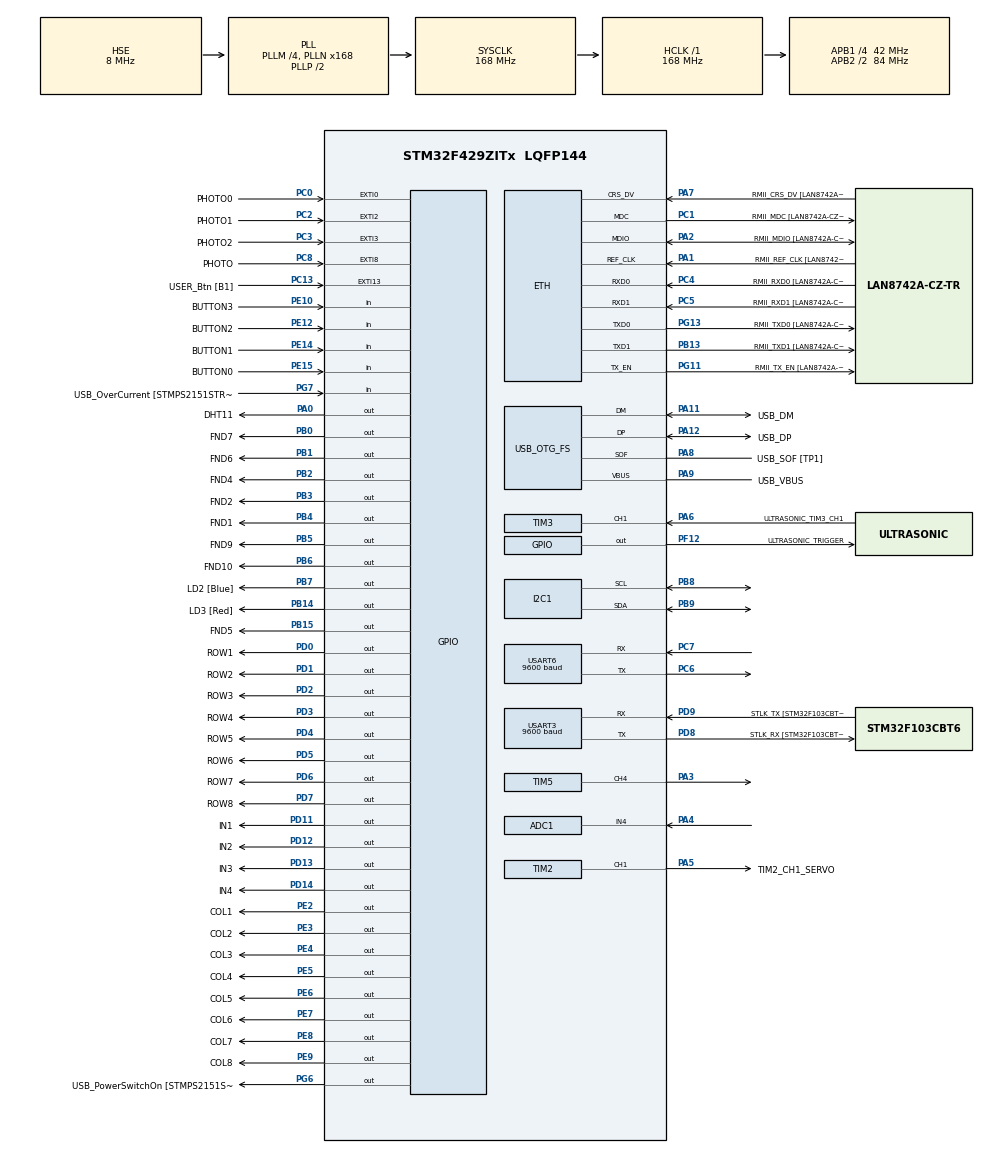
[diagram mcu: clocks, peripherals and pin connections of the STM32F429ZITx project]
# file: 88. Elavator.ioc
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ADC1.Channel-1\#ChannelRegularConversion=ADC_CHANNEL_4
ADC1.ContinuousConvMode=ENABLE
ADC1.NbrOfConversionFlag=1
ADC1.Rank-1\#ChannelRegularConversion=1
ADC1.SamplingTime-1\#ChannelRegularConversion=ADC_SAMPLETIME_480CYCLES
ADC1.master=1
ETH.MediaInterface=HAL_ETH_RMII_MODE
FREERTOS.Mutexes01=myMutex01,Dynamic,NULL
FREERTOS.Tasks01=defaultTask,24,128,StartDefaultTask,Default,NULL,Dynamic,NULL,NULL;Task1,8,128,Task1_func,Default,NULL,Dynamic,NULL,NULL;Task2,8,128,Task2_func,Default,NULL,Dynamic,NULL,NULL;Task3,8,128,Task3_func,Default,NULL,Dynamic,NULL,NULL
FREERTOS.configUSE_NEWLIB_REENTRANT=1
Mcu.Family=STM32F4
Mcu.Name=STM32F429ZITx
Mcu.Package=LQFP144
NVIC.ADC_IRQn=true\:5\:0\:false\:false\:true\:true\:true\:true\:true
NVIC.EXTI0_IRQn=true\:5\:0\:false\:false\:true\:true\:true\:true\:true
NVIC.EXTI2_IRQn=true\:5\:0\:false\:false\:true\:true\:true\:true\:true
NVIC.EXTI3_IRQn=true\:5\:0\:false\:false\:true\:true\:true\:true\:true
NVIC.EXTI9_5_IRQn=true\:5\:0\:false\:false\:true\:true\:true\:true\:true
NVIC.PriorityGroup=NVIC_PRIORITYGROUP_4
NVIC.TIM1_TRG_COM_TIM11_IRQn=true\:5\:0\:false\:false\:true\:true\:true\:true\:true
NVIC.TIM1_UP_TIM10_IRQn=true\:5\:0\:false\:false\:true\:true\:true\:true\:true
NVIC.TIM2_IRQn=true\:5\:0\:false\:false\:true\:true\:true\:true\:true
NVIC.TIM3_IRQn=true\:5\:0\:false\:false\:true\:true\:true\:true\:true
NVIC.TIM4_IRQn=true\:5\:0\:false\:false\:true\:true\:true\:true\:true
NVIC.TIM5_IRQn=true\:5\:0\:false\:false\:true\:true\:true\:true\:true
NVIC.TIM6_DAC_IRQn=true\:15\:0\:false\:false\:true\:false\:false\:true\:true
NVIC.TimeBase=TIM6_DAC_IRQn
NVIC.TimeBaseIP=TIM6
NVIC.USART3_IRQn=true\:5\:0\:false\:false\:true\:true\:true\:true\:true
NVIC.USART6_IRQn=true\:5\:0\:false\:false\:true\:true\:true\:true\:true
PA0/WKUP.GPIO_Label=DHT11
PA0/WKUP.Signal=GPIO_Output
PA1.GPIO_Label=RMII_REF_CLK [LAN8742A-CZ-TR_REFCLK0]
PA1.Mode=RMII
PA1.Signal=ETH_REF_CLK
PA10.GPIO_Label=USB_ID
PA10.Signal=USB_OTG_FS_ID
PA11.GPIO_Label=USB_DM
PA11.Mode=Device_Only
PA11.Signal=USB_OTG_FS_DM
PA12.GPIO_Label=USB_DP
PA12.Mode=Device_Only
PA12.Signal=USB_OTG_FS_DP
PA13.GPIO_Label=TMS
PA13.Mode=Serial_Wire
PA13.Signal=SYS_JTMS-SWDIO
PA14.GPIO_Label=TCK
PA14.Mode=Serial_Wire
PA14.Signal=SYS_JTCK-SWCLK
PA2.GPIO_Label=RMII_MDIO [LAN8742A-CZ-TR_MDIO]
PA2.Mode=RMII
PA2.Signal=ETH_MDIO
PA3.Signal=S_TIM5_CH4
PA4.Signal=ADCx_IN4
PA5.GPIO_Label=TIM2_CH1_SERVO
PA5.Signal=S_TIM2_CH1_ETR
PA6.GPIO_Label=ULTRASONIC_TIM3_CH1
PA6.Signal=S_TIM3_CH1
PA7.GPIO_Label=RMII_CRS_DV [LAN8742A-CZ-TR_CRS_DV]
PA7.Mode=RMII
PA7.Signal=ETH_CRS_DV
PA8.GPIO_Label=USB_SOF [TP1]
PA8.Mode=Activate_SOF_FS
PA8.Signal=USB_OTG_FS_SOF
PA9.GPIO_Label=USB_VBUS
PA9.Mode=Activate_VBUS
PA9.Signal=USB_OTG_FS_VBUS
PB0.GPIO_Label=FND7
PB0.Signal=GPIO_Output
PB1.GPIO_Label=FND6
PB1.Signal=GPIO_Output
PB13.GPIO_Label=RMII_TXD1 [LAN8742A-CZ-TR_TXD1]
PB13.Mode=RMII
PB13.Signal=ETH_TXD1
PB14.GPIO_Label=LD3 [Red]
PB14.Signal=GPIO_Output
PB15.GPIO_Label=FND5
PB15.Signal=GPIO_Output
PB2/BOOT1.GPIO_Label=FND4
PB2/BOOT1.Signal=GPIO_Output
PB3.GPIO_Label=FND2
PB3.Signal=GPIO_Output
PB4.GPIO_Label=FND1
PB4.Signal=GPIO_Output
PB5.GPIO_Label=FND9
PB5.Signal=GPIO_Output
PB6.GPIO_Label=FND10
PB6.Signal=GPIO_Output
PB7.GPIO_Label=LD2 [Blue]
PB7.Signal=GPIO_Output
PB8.Mode=I2C
PB8.Signal=I2C1_SCL
PB9.Mode=I2C
PB9.Signal=I2C1_SDA
PC0.GPIO_Label=PHOTO0
PC0.Signal=GPXTI0
PC1.GPIO_Label=RMII_MDC [LAN8742A-CZ-TR_MDC]
PC1.Mode=RMII
PC1.Signal=ETH_MDC
PC13.GPIO_Label=USER_Btn [B1]
PC13.Signal=GPXTI13
PC14/OSC32_IN.Mode=LSE-External-Oscillator
PC14/OSC32_IN.Signal=RCC_OSC32_IN
PC15/OSC32_OUT.Mode=LSE-External-Oscillator
PC15/OSC32_OUT.Signal=RCC_OSC32_OUT
PC2.GPIO_Label=PHOTO1
PC2.Signal=GPXTI2
PC3.GPIO_Label=PHOTO2
PC3.Signal=GPXTI3
PC4.GPIO_Label=RMII_RXD0 [LAN8742A-CZ-TR_RXD0]
PC4.Mode=RMII
PC4.Signal=ETH_RXD0
PC5.GPIO_Label=RMII_RXD1 [LAN8742A-CZ-TR_RXD1]
PC5.Mode=RMII
PC5.Signal=ETH_RXD1
PC6.Mode=Asynchronous
PC6.Signal=USART6_TX
PC7.Mode=Asynchronous
PC7.Signal=USART6_RX
PC8.GPIO_Label=PHOTO
PC8.Signal=GPXTI8
PD0.GPIO_Label=ROW1
PD0.Signal=GPIO_Output
PD1.GPIO_Label=ROW2
PD1.Signal=GPIO_Output
PD11.GPIO_Label=IN1
PD11.Signal=GPIO_Output
PD12.GPIO_Label=IN2
PD12.Signal=GPIO_Output
PD13.GPIO_Label=IN3
PD13.Signal=GPIO_Output
PD14.GPIO_Label=IN4
PD14.Signal=GPIO_Output
PD2.GPIO_Label=ROW3
PD2.Signal=GPIO_Output
PD3.GPIO_Label=ROW4
PD3.Signal=GPIO_Output
PD4.GPIO_Label=ROW5
PD4.Signal=GPIO_Output
PD5.GPIO_Label=ROW6
PD5.Signal=GPIO_Output
PD6.GPIO_Label=ROW7
PD6.Signal=GPIO_Output
PD7.GPIO_Label=ROW8
PD7.Signal=GPIO_Output
PD8.GPIO_Label=STLK_RX [STM32F103CBT6_PA3]
PD8.Mode=Asynchronous
PD8.Signal=USART3_TX
PD9.GPIO_Label=STLK_TX [STM32F103CBT6_PA2]
PD9.Mode=Asynchronous
PD9.Signal=USART3_RX
PE10.GPIO_Label=BUTTON3
PE10.Signal=GPIO_Input
PE12.GPIO_Label=BUTTON2
PE12.Signal=GPIO_Input
PE14.GPIO_Label=BUTTON1
PE14.Signal=GPIO_Input
PE15.GPIO_Label=BUTTON0
PE15.Signal=GPIO_Input
PE2.GPIO_Label=COL1
PE2.Signal=GPIO_Output
PE3.GPIO_Label=COL2
PE3.Signal=GPIO_Output
PE4.GPIO_Label=COL3
PE4.Signal=GPIO_Output
PE5.GPIO_Label=COL4
PE5.Signal=GPIO_Output
PE6.GPIO_Label=COL5
PE6.Signal=GPIO_Output
PE7.GPIO_Label=COL6
PE7.Signal=GPIO_Output
PE8.GPIO_Label=COL7
PE8.Signal=GPIO_Output
PE9.GPIO_Label=COL8
PE9.Signal=GPIO_Output
PF12.GPIO_Label=ULTRASONIC_TRIGGER
PF12.Signal=GPIO_Output
PG11.GPIO_Label=RMII_TX_EN [LAN8742A-CZ-TR_TXEN]
PG11.Mode=RMII
PG11.Signal=ETH_TX_EN
PG13.GPIO_Label=RMII_TXD0 [LAN8742A-CZ-TR_TXD0]
PG13.Mode=RMII
PG13.Signal=ETH_TXD0
PG6.GPIO_Label=USB_PowerSwitchOn [STMPS2151STR_EN]
PG6.Signal=GPIO_Output
PG7.GPIO_Label=USB_OverCurrent [STMPS2151STR_FAULT]
PG7.Signal=GPIO_Input
PH0/OSC_IN.GPIO_Label=MCO [STM32F103CBT6_PA8]
PH0/OSC_IN.Mode=HSE-External-Clock-Source
PH0/OSC_IN.Signal=RCC_OSC_IN
PH1/OSC_OUT.Mode=HSE-External-Clock-Source
PH1/OSC_OUT.Signal=RCC_OSC_OUT
ProjectManager.HeapSize=0x200
ProjectManager.StackSize=0x400
ProjectManager.TargetToolchain=STM32CubeIDE
RCC.48MHZClocksFreq_Value=48000000
RCC.AHBFreq_Value=168000000
RCC.APB1CLKDivider=RCC_HCLK_DIV4
RCC.APB1Freq_Value=42000000
RCC.APB1TimFreq_Value=84000000
RCC.APB2CLKDivider=RCC_HCLK_DIV2
RCC.APB2Freq_Value=84000000
RCC.APB2TimCLKDivider=2
RCC.APB2TimFreq_Value=168000000
RCC.CortexFreq_Value=168000000
RCC.HCLKFreq_Value=168000000
RCC.HSE_VALUE=8000000
RCC.HSI_VALUE=16000000
RCC.PLLM=4
RCC.PLLMUL=RCC_PLL_MUL9
RCC.PLLN=168
RCC.PLLQ=7
RCC.PRESCALERUSB=RCC_USBCLKSOURCE_PLL_DIV1_5
RCC.SYSCLKFreq_VALUE=168000000
RCC.SYSCLKSource=RCC_SYSCLKSOURCE_PLLCLK
RCC.SYSCLKSourceVirtual=RCC_SYSCLKSOURCE_PLLCLK
RCC.USBFreq_Value=48000000
RCC.VCOOutputFreq_Value=336000000
RTC.Date=16
RTC.Hours=9
RTC.Minutes=38
RTC.Month=RTC_MONTH_OCTOBER
RTC.Year=23
SH.ADCx_IN4.0=ADC1_IN4,IN4
SH.S_TIM2_CH1_ETR.0=TIM2_CH1,PWM Generation1 CH1
SH.S_TIM3_CH1.0=TIM3_CH1,Input_Capture1_from_TI1
SH.S_TIM5_CH4.0=TIM5_CH4,PWM Generation4 CH4
TIM10.Period=10000-1
TIM10.Prescaler=168-1
TIM11.Prescaler=168-1
TIM2.Channel-PWM\ Generation1\ CH1=TIM_CHANNEL_1
TIM2.Period=1000-1
TIM2.Prescaler=1680-1
TIM2.Pulse-PWM\ Generation1\ CH1=500-1
TIM3.Channel-Input_Capture1_from_TI1=TIM_CHANNEL_1
TIM3.ICPolarity_CH1=TIM_INPUTCHANNELPOLARITY_BOTHEDGE
TIM3.Prescaler=84-1
TIM4.Period=100-1
TIM4.Prescaler=840-1
TIM5.Channel-PWM\ Generation4\ CH4=TIM_CHANNEL_4
TIM5.Period=400-1
TIM5.Prescaler=52.5-1
TIM5.Pulse-PWM\ Generation4\ CH4=200-1
USART3.BaudRate=9600
USART3.VirtualMode=VM_ASYNC
USART6.BaudRate=9600
USART6.VirtualMode=VM_ASYNC
USB_OTG_FS.VirtualMode=Device_Only
VP_FREERTOS_VS_CMSIS_V2.Mode=CMSIS_V2
VP_RTC_VS_RTC_Activate.Mode=RTC_Enabled
VP_RTC_VS_RTC_Calendar.Mode=RTC_Calendar
VP_SYS_VS_tim6.Mode=TIM6
VP_TIM10_VS_ClockSourceINT.Mode=Enable_Timer
VP_TIM11_VS_ClockSourceINT.Mode=Enable_Timer
VP_TIM4_VS_ClockSourceINT.Mode=Internal
VP_TIM5_VS_ClockSourceINT.Mode=Internal
board=NUCLEO-F429ZI

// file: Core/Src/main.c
/* USER CODE BEGIN Header */
/**
  ******************************************************************************
  * @file           : main.c
  * @brief          : Main program body
  ******************************************************************************
  * @attention
  *
  * Copyright (c) 2023 STMicroelectronics.
  * All rights reserved.
  *
  * This software is licensed under terms that can be found in the LICENSE file
  * in the root directory of this software component.
  * If no LICENSE file comes with this software, it is provided AS-IS.
  *
  ******************************************************************************
  */
/* USER CODE END Header */
#include "main.h"
#include "string.h"
#include "cmsis_os.h"

ETH_TxPacketConfig TxConfig;
ETH_DMADescTypeDef  DMARxDscrTab[ETH_RX_DESC_CNT]; /* Ethernet Rx DMA Descriptors */
ETH_DMADescTypeDef  DMATxDscrTab[ETH_TX_DESC_CNT]; /* Ethernet Tx DMA Descriptors */

ADC_HandleTypeDef hadc1;

ETH_HandleTypeDef heth;

I2C_HandleTypeDef hi2c1;

RTC_HandleTypeDef hrtc;

TIM_HandleTypeDef htim2;
TIM_HandleTypeDef htim3;
TIM_HandleTypeDef htim4;
TIM_HandleTypeDef htim5;
TIM_HandleTypeDef htim10;
TIM_HandleTypeDef htim11;

UART_HandleTypeDef huart3;
UART_HandleTypeDef huart6;

PCD_HandleTypeDef hpcd_USB_OTG_FS;

/* Definitions for defaultTask */
osThreadId_t defaultTaskHandle;
const osThreadAttr_t defaultTask_attributes = {
  .name = "defaultTask",
  .stack_size = 128 * 4,
  .priority = (osPriority_t) osPriorityNormal,
};
/* Definitions for Task1 */
osThreadId_t Task1Handle;
const osThreadAttr_t Task1_attributes = {
  .name = "Task1",
  .stack_size = 128 * 4,
  .priority = (osPriority_t) osPriorityLow,
};
/* Definitions for Task2 */
osThreadId_t Task2Handle;
const osThreadAttr_t Task2_attributes = {
  .name = "Task2",
  .stack_size = 128 * 4,
  .priority = (osPriority_t) osPriorityLow,
};
/* Definitions for Task3 */
osThreadId_t Task3Handle;
const osThreadAttr_t Task3_attributes = {
  .name = "Task3",
  .stack_size = 128 * 4,
  .priority = (osPriority_t) osPriorityLow,
};
/* Definitions for myMutex01 */
osMutexId_t myMutex01Handle;
const osMutexAttr_t myMutex01_attributes = {
  .name = "myMutex01"
};
/* USER CODE BEGIN PV */
uint8_t rx_data;   // uart3 rx data
uint8_t bt_rx_data;   // uart6 bt rx data
volatile int TIM10_10ms_counter=0;
volatile int TIM10_10ms_ultrasonic=0;
/* USER CODE END PV */

void SystemClock_Config(void);
static void MX_GPIO_Init(void);
static void MX_USART3_UART_Init(void);
static void MX_USB_OTG_FS_PCD_Init(void);
static void MX_USART6_UART_Init(void);
static void MX_TIM10_Init(void);
static void MX_TIM11_Init(void);
static void MX_TIM3_Init(void);
static void MX_TIM4_Init(void);
static void MX_TIM2_Init(void);
static void MX_RTC_Init(void);
static void MX_TIM5_Init(void);
static void MX_I2C1_Init(void);
static void MX_ADC1_Init(void);
static void MX_ETH_Init(void);
void StartDefaultTask(void *argument);
void Task1_func(void *argument);
void Task2_func(void *argument);
void Task3_func(void *argument);

/* USER CODE BEGIN PFP */
extern void led_main(void);
extern void pc_command_processing(void);
extern void bt_command_processing(void);
extern void DHT11_main(void);
extern void DHT11_Init(void);
extern void DHT11_processing(void);
extern void ultrasonic_processing(void);
extern void i2c_lcd_main(void);
extern void i2c_lcd_init(void);
extern void lcd_string(uint8_t *str);
extern void move_cursor(uint8_t row, uint8_t column);
extern void dcmotor_pwm_control(void);
extern void servo_motor_test_main(void);
extern void get_rtc(void);
extern void lcd_display_mode_select(void);
extern void set_time_button_ui(void);
extern void buzzer_main();
extern int dotmatrix_main_test();
extern void set_rpm(int rpm);
extern void stepmotor_main(void);
extern void stepmotor_drive(int step);
extern int fnd();
void delay_us(unsigned long us);
/* USER CODE END PFP */

/* USER CODE BEGIN 0 */
//---------------
// call by SysTick_Handler of stm32f4xx_it.c
// ARM default timer
// enter here every 1ms
volatile int t1ms_counter=0;  // volatile : for disable optimize
void HAL_SYSTICK_Handler(void)
{
	t1ms_counter++;   // 1ms timer
}
//----------  printf start ----------
#ifdef __GNUC__
/* With GCC, small printf (option LD Linker->Libraries->Small printf
   set to 'Yes') calls __io_putchar() */
#define PUTCHAR_PROTOTYPE int __io_putchar(int ch)
#else
#define PUTCHAR_PROTOTYPE int fputc(int ch, FILE *f)
#endif /* __GNUC_ */
/**
  * @brief  Retargets the C library printf function to the USART.
  * @param  None
  * @retval None
  */
PUTCHAR_PROTOTYPE   // Add for printf
{
  /* Place your implementation of fputc here */
  /* e.g. write a character to the USART3 and Loop until the end of transmission */
  HAL_UART_Transmit(&huart3, (uint8_t *)&ch, 1, 0xFFFF);

  return ch;
}
//----------  printf end ----------

void delay_us(unsigned long us)
{
	__HAL_TIM_SET_COUNTER(&htim11,0);   // tim11 clear
	while(__HAL_TIM_GET_COUNTER(&htim11) < us)
		;
}

// 1. MOVE FROM DRIVER /STM32F4XX_HAL_DRIVER/SRC/STM32F4XX_HAL_GPIO...
// 2. ENTER HERE EVERY EXTERNAL INTERRUPT
volatile int ext_int_no = -1; // EXTERNAL INTERRUPT?��?��?�� volatile?�� ?��?��.
volatile int floor_state = 0;

void HAL_GPIO_EXTI_Callback(uint16_t GPIO_Pin)
{
  switch(GPIO_Pin)
  {

  case PHOTO0_Pin:
	  ext_int_no=GPIO_Pin;
	  floor_state=4;
	  init_dotmatrix();
	  HAL_GPIO_TogglePin(GPIOB, GPIO_PIN_0);
  	  break;
  case PHOTO1_Pin:
	  ext_int_no=GPIO_Pin;
	  floor_state=3;

	  init_dotmatrix();
	  HAL_GPIO_TogglePin(GPIOB, GPIO_PIN_7);
  	  break;
  case PHOTO2_Pin:
	  ext_int_no=GPIO_Pin;
	  floor_state=2;

	  init_dotmatrix();
	  HAL_GPIO_TogglePin(GPIOB, GPIO_PIN_14);
  	  break;
  case PHOTO_Pin:
	  ext_int_no=GPIO_Pin;
	  floor_state=1;
	  init_dotmatrix();
	  HAL_GPIO_TogglePin(GPIOB, GPIO_PIN_0);
  	  break;

  }
  UNUSED(GPIO_Pin);
}
uint16_t adcValue[4];
void HAL_ADC_ConvCpltCallback(ADC_HandleTypeDef* hadc)
{
	if(hadc ->Instance == ADC1)
	{
		adcValue[0] = HAL_ADC_GetValue(&hadc1);
		HAL_ADC_Start_IT(&hadc1);
	}

}
/* USER CODE END 0 */

int main(void)
{

  /* MCU Configuration--------------------------------------------------------*/

  /* Reset of all peripherals, Initializes the Flash interface and the Systick. */
  HAL_Init();

  /* Configure the system clock */
  SystemClock_Config();

  /* Initialize all configured peripherals */
  MX_GPIO_Init();
  MX_USART3_UART_Init();
  MX_USB_OTG_FS_PCD_Init();
  MX_USART6_UART_Init();
  MX_TIM10_Init();
  MX_TIM11_Init();
  MX_TIM3_Init();
  MX_TIM4_Init();
  MX_TIM2_Init();
  MX_RTC_Init();
  MX_TIM5_Init();
  MX_I2C1_Init();
  MX_ADC1_Init();
  MX_ETH_Init();
  /* USER CODE BEGIN 2 */
  HAL_UART_Receive_IT(&huart3, &rx_data, 1);   // assing to RX INT
  HAL_UART_Receive_IT(&huart6, &bt_rx_data, 1);   // for BT assing to RX INT
  HAL_TIM_Base_Start_IT(&htim10);   // ADD_SIKWON_1011
  HAL_TIM_Base_Start_IT(&htim11);   // ADD_SIKWON_1011
  HAL_TIM_IC_Start_IT(&htim3, TIM_CHANNEL_1);   // for count pulse(rising edge & falling edge)
  HAL_TIM_PWM_Start_IT(&htim4, TIM_CHANNEL_1);  // for DC motor PWM control
  HAL_TIM_PWM_Start(&htim2, TIM_CHANNEL_1);   // for SERVO motor PWM control
  HAL_TIM_PWM_Start(&htim5, TIM_CHANNEL_4);   // PIEZO Buzzer
  HAL_ADC_Start_IT(&hadc1);

//  DHT11_Init();
  i2c_lcd_init();

  TIM10_10ms_counter=0;

//  led_main();
//  DHT11_main();
//  i2c_lcd_main();
//  servo_motor_test_main();
//    buzzer_main();

  /* USER CODE END 2 */

  /* Init scheduler */
  osKernelInitialize();
  /* Create the mutex(es) */
  /* creation of myMutex01 */
  myMutex01Handle = osMutexNew(&myMutex01_attributes);

  /* Create the thread(s) */
  /* creation of defaultTask */
  defaultTaskHandle = osThreadNew(StartDefaultTask, NULL, &defaultTask_attributes);

  /* creation of Task1 */
  Task1Handle = osThreadNew(Task1_func, NULL, &Task1_attributes);

  /* creation of Task2 */
  Task2Handle = osThreadNew(Task2_func, NULL, &Task2_attributes);

  /* creation of Task3 */
  Task3Handle = osThreadNew(Task3_func, NULL, &Task3_attributes);

  /* Start scheduler */
  osKernelStart();
  /* We should never get here as control is now taken by the scheduler */
  /* Infinite loop */
  /* USER CODE BEGIN WHILE */
  //dotmatrix_main_test();

  while (1)
  {

	 // stepmotor_main_test();

	//stepmotor_main_test();

/*	DHT11_processing();
 	pc_command_processing();
 	bt_command_processing();
 	ultrasonic_processing();
 	dcmotor_pwm_control();
 	get_rtc();
 	lcd_display_mode_select();
 	set_time_button_ui();*/
    /* USER CODE END WHILE */

  }
}

void SystemClock_Config(void)
{
  RCC_OscInitTypeDef RCC_OscInitStruct = {0};
  RCC_ClkInitTypeDef RCC_ClkInitStruct = {0};

  /** Configure the main internal regulator output voltage
  */
  __HAL_RCC_PWR_CLK_ENABLE();
  __HAL_PWR_VOLTAGESCALING_CONFIG(PWR_REGULATOR_VOLTAGE_SCALE1);

  /** Initializes the RCC Oscillators according to the specified parameters
  * in the RCC_OscInitTypeDef structure.
  */
  RCC_OscInitStruct.OscillatorType = RCC_OSCILLATORTYPE_LSI|RCC_OSCILLATORTYPE_HSE;
  RCC_OscInitStruct.HSEState = RCC_HSE_BYPASS;
  RCC_OscInitStruct.LSIState = RCC_LSI_ON;
  RCC_OscInitStruct.PLL.PLLState = RCC_PLL_ON;
  RCC_OscInitStruct.PLL.PLLSource = RCC_PLLSOURCE_HSE;
  RCC_OscInitStruct.PLL.PLLM = 4;
  RCC_OscInitStruct.PLL.PLLN = 168;
  RCC_OscInitStruct.PLL.PLLP = RCC_PLLP_DIV2;
  RCC_OscInitStruct.PLL.PLLQ = 7;
  if (HAL_RCC_OscConfig(&RCC_OscInitStruct) != HAL_OK)
  {
    Error_Handler();
  }

  /** Initializes the CPU, AHB and APB buses clocks
  */
  RCC_ClkInitStruct.ClockType = RCC_CLOCKTYPE_HCLK|RCC_CLOCKTYPE_SYSCLK
                              |RCC_CLOCKTYPE_PCLK1|RCC_CLOCKTYPE_PCLK2;
  RCC_ClkInitStruct.SYSCLKSource = RCC_SYSCLKSOURCE_PLLCLK;
  RCC_ClkInitStruct.AHBCLKDivider = RCC_SYSCLK_DIV1;
  RCC_ClkInitStruct.APB1CLKDivider = RCC_HCLK_DIV4;
  RCC_ClkInitStruct.APB2CLKDivider = RCC_HCLK_DIV2;

  if (HAL_RCC_ClockConfig(&RCC_ClkInitStruct, FLASH_LATENCY_5) != HAL_OK)
  {
    Error_Handler();
  }
}

static void MX_ADC1_Init(void)
{

  ADC_ChannelConfTypeDef sConfig = {0};

  /** Configure the global features of the ADC (Clock, Resolution, Data Alignment and number of conversion)
  */
  hadc1.Instance = ADC1;
  hadc1.Init.ClockPrescaler = ADC_CLOCK_SYNC_PCLK_DIV4;
  hadc1.Init.Resolution = ADC_RESOLUTION_12B;
  hadc1.Init.ScanConvMode = DISABLE;
  hadc1.Init.ContinuousConvMode = ENABLE;
  hadc1.Init.DiscontinuousConvMode = DISABLE;
  hadc1.Init.ExternalTrigConvEdge = ADC_EXTERNALTRIGCONVEDGE_NONE;
  hadc1.Init.ExternalTrigConv = ADC_SOFTWARE_START;
  hadc1.Init.DataAlign = ADC_DATAALIGN_RIGHT;
  hadc1.Init.NbrOfConversion = 1;
  hadc1.Init.DMAContinuousRequests = DISABLE;
  hadc1.Init.EOCSelection = ADC_EOC_SINGLE_CONV;
  if (HAL_ADC_Init(&hadc1) != HAL_OK)
  {
    Error_Handler();
  }

  /** Configure for the selected ADC regular channel its corresponding rank in the sequencer and its sample time.
  */
  sConfig.Channel = ADC_CHANNEL_4;
  sConfig.Rank = 1;
  sConfig.SamplingTime = ADC_SAMPLETIME_480CYCLES;
  if (HAL_ADC_ConfigChannel(&hadc1, &sConfig) != HAL_OK)
  {
    Error_Handler();
  }

}

static void MX_ETH_Init(void)
{

   static uint8_t MACAddr[6];

  heth.Instance = ETH;
  MACAddr[0] = 0x00;
  MACAddr[1] = 0x80;
  MACAddr[2] = 0xE1;
  MACAddr[3] = 0x00;
  MACAddr[4] = 0x00;
  MACAddr[5] = 0x00;
  heth.Init.MACAddr = &MACAddr[0];
  heth.Init.MediaInterface = HAL_ETH_RMII_MODE;
  heth.Init.TxDesc = DMATxDscrTab;
  heth.Init.RxDesc = DMARxDscrTab;
  heth.Init.RxBuffLen = 1524;

  if (HAL_ETH_Init(&heth) != HAL_OK)
  {
    Error_Handler();
  }

  memset(&TxConfig, 0 , sizeof(ETH_TxPacketConfig));
  TxConfig.Attributes = ETH_TX_PACKETS_FEATURES_CSUM | ETH_TX_PACKETS_FEATURES_CRCPAD;
  TxConfig.ChecksumCtrl = ETH_CHECKSUM_IPHDR_PAYLOAD_INSERT_PHDR_CALC;
  TxConfig.CRCPadCtrl = ETH_CRC_PAD_INSERT;

}

static void MX_I2C1_Init(void)
{

  hi2c1.Instance = I2C1;
  hi2c1.Init.ClockSpeed = 100000;
  hi2c1.Init.DutyCycle = I2C_DUTYCYCLE_2;
  hi2c1.Init.OwnAddress1 = 0;
  hi2c1.Init.AddressingMode = I2C_ADDRESSINGMODE_7BIT;
  hi2c1.Init.DualAddressMode = I2C_DUALADDRESS_DISABLE;
  hi2c1.Init.OwnAddress2 = 0;
  hi2c1.Init.GeneralCallMode = I2C_GENERALCALL_DISABLE;
  hi2c1.Init.NoStretchMode = I2C_NOSTRETCH_DISABLE;
  if (HAL_I2C_Init(&hi2c1) != HAL_OK)
  {
    Error_Handler();
  }

  /** Configure Analogue filter
  */
  if (HAL_I2CEx_ConfigAnalogFilter(&hi2c1, I2C_ANALOGFILTER_ENABLE) != HAL_OK)
  {
    Error_Handler();
  }

  /** Configure Digital filter
  */
  if (HAL_I2CEx_ConfigDigitalFilter(&hi2c1, 0) != HAL_OK)
  {
    Error_Handler();
  }

}

static void MX_RTC_Init(void)
{

  RTC_TimeTypeDef sTime = {0};
  RTC_DateTypeDef sDate = {0};

  /** Initialize RTC Only
  */
  hrtc.Instance = RTC;
  hrtc.Init.HourFormat = RTC_HOURFORMAT_24;
  hrtc.Init.AsynchPrediv = 127;
  hrtc.Init.SynchPrediv = 255;
  hrtc.Init.OutPut = RTC_OUTPUT_DISABLE;
  hrtc.Init.OutPutPolarity = RTC_OUTPUT_POLARITY_HIGH;
  hrtc.Init.OutPutType = RTC_OUTPUT_TYPE_OPENDRAIN;
  if (HAL_RTC_Init(&hrtc) != HAL_OK)
  {
    Error_Handler();
  }

  /** Initialize RTC and set the Time and Date
  */
  sTime.Hours = 0x9;
  sTime.Minutes = 0x38;
  sTime.Seconds = 0x0;
  sTime.DayLightSaving = RTC_DAYLIGHTSAVING_NONE;
  sTime.StoreOperation = RTC_STOREOPERATION_RESET;
  if (HAL_RTC_SetTime(&hrtc, &sTime, RTC_FORMAT_BCD) != HAL_OK)
  {
    Error_Handler();
  }
  sDate.WeekDay = RTC_WEEKDAY_MONDAY;
  sDate.Month = RTC_MONTH_OCTOBER;
  sDate.Date = 0x16;
  sDate.Year = 0x23;

  if (HAL_RTC_SetDate(&hrtc, &sDate, RTC_FORMAT_BCD) != HAL_OK)
  {
    Error_Handler();
  }

}

static void MX_TIM2_Init(void)
{

  TIM_MasterConfigTypeDef sMasterConfig = {0};
  TIM_OC_InitTypeDef sConfigOC = {0};

  htim2.Instance = TIM2;
  htim2.Init.Prescaler = 1680-1;
  htim2.Init.CounterMode = TIM_COUNTERMODE_UP;
  htim2.Init.Period = 1000-1;
  htim2.Init.ClockDivision = TIM_CLOCKDIVISION_DIV1;
  htim2.Init.AutoReloadPreload = TIM_AUTORELOAD_PRELOAD_DISABLE;
  if (HAL_TIM_PWM_Init(&htim2) != HAL_OK)
  {
    Error_Handler();
  }
  sMasterConfig.MasterOutputTrigger = TIM_TRGO_RESET;
  sMasterConfig.MasterSlaveMode = TIM_MASTERSLAVEMODE_DISABLE;
  if (HAL_TIMEx_MasterConfigSynchronization(&htim2, &sMasterConfig) != HAL_OK)
  {
    Error_Handler();
  }
  sConfigOC.OCMode = TIM_OCMODE_PWM1;
  sConfigOC.Pulse = 500-1;
  sConfigOC.OCPolarity = TIM_OCPOLARITY_HIGH;
  sConfigOC.OCFastMode = TIM_OCFAST_DISABLE;
  if (HAL_TIM_PWM_ConfigChannel(&htim2, &sConfigOC, TIM_CHANNEL_1) != HAL_OK)
  {
    Error_Handler();
  }
  HAL_TIM_MspPostInit(&htim2);

}

static void MX_TIM3_Init(void)
{

  TIM_MasterConfigTypeDef sMasterConfig = {0};
  TIM_IC_InitTypeDef sConfigIC = {0};

  htim3.Instance = TIM3;
  htim3.Init.Prescaler = 84-1;
  htim3.Init.CounterMode = TIM_COUNTERMODE_UP;
  htim3.Init.Period = 65535;
  htim3.Init.ClockDivision = TIM_CLOCKDIVISION_DIV1;
  htim3.Init.AutoReloadPreload = TIM_AUTORELOAD_PRELOAD_DISABLE;
  if (HAL_TIM_IC_Init(&htim3) != HAL_OK)
  {
    Error_Handler();
  }
  sMasterConfig.MasterOutputTrigger = TIM_TRGO_RESET;
  sMasterConfig.MasterSlaveMode = TIM_MASTERSLAVEMODE_DISABLE;
  if (HAL_TIMEx_MasterConfigSynchronization(&htim3, &sMasterConfig) != HAL_OK)
  {
    Error_Handler();
  }
  sConfigIC.ICPolarity = TIM_INPUTCHANNELPOLARITY_BOTHEDGE;
  sConfigIC.ICSelection = TIM_ICSELECTION_DIRECTTI;
  sConfigIC.ICPrescaler = TIM_ICPSC_DIV1;
  sConfigIC.ICFilter = 0;
  if (HAL_TIM_IC_ConfigChannel(&htim3, &sConfigIC, TIM_CHANNEL_1) != HAL_OK)
  {
    Error_Handler();
  }

}

static void MX_TIM4_Init(void)
{

  TIM_ClockConfigTypeDef sClockSourceConfig = {0};
  TIM_MasterConfigTypeDef sMasterConfig = {0};

  htim4.Instance = TIM4;
  htim4.Init.Prescaler = 840-1;
  htim4.Init.CounterMode = TIM_COUNTERMODE_UP;
  htim4.Init.Period = 100-1;
  htim4.Init.ClockDivision = TIM_CLOCKDIVISION_DIV1;
  htim4.Init.AutoReloadPreload = TIM_AUTORELOAD_PRELOAD_DISABLE;
  if (HAL_TIM_Base_Init(&htim4) != HAL_OK)
  {
    Error_Handler();
  }
  sClockSourceConfig.ClockSource = TIM_CLOCKSOURCE_INTERNAL;
  if (HAL_TIM_ConfigClockSource(&htim4, &sClockSourceConfig) != HAL_OK)
  {
    Error_Handler();
  }
  sMasterConfig.MasterOutputTrigger = TIM_TRGO_RESET;
  sMasterConfig.MasterSlaveMode = TIM_MASTERSLAVEMODE_DISABLE;
  if (HAL_TIMEx_MasterConfigSynchronization(&htim4, &sMasterConfig) != HAL_OK)
  {
    Error_Handler();
  }

}

static void MX_TIM5_Init(void)
{

  TIM_ClockConfigTypeDef sClockSourceConfig = {0};
  TIM_MasterConfigTypeDef sMasterConfig = {0};
  TIM_OC_InitTypeDef sConfigOC = {0};

  htim5.Instance = TIM5;
  htim5.Init.Prescaler = 52.5-1;
  htim5.Init.CounterMode = TIM_COUNTERMODE_UP;
  htim5.Init.Period = 400-1;
  htim5.Init.ClockDivision = TIM_CLOCKDIVISION_DIV1;
  htim5.Init.AutoReloadPreload = TIM_AUTORELOAD_PRELOAD_DISABLE;
  if (HAL_TIM_Base_Init(&htim5) != HAL_OK)
  {
    Error_Handler();
  }
  sClockSourceConfig.ClockSource = TIM_CLOCKSOURCE_INTERNAL;
  if (HAL_TIM_ConfigClockSource(&htim5, &sClockSourceConfig) != HAL_OK)
  {
    Error_Handler();
  }
  if (HAL_TIM_PWM_Init(&htim5) != HAL_OK)
  {
    Error_Handler();
  }
  sMasterConfig.MasterOutputTrigger = TIM_TRGO_RESET;
  sMasterConfig.MasterSlaveMode = TIM_MASTERSLAVEMODE_DISABLE;
  if (HAL_TIMEx_MasterConfigSynchronization(&htim5, &sMasterConfig) != HAL_OK)
  {
    Error_Handler();
  }
  sConfigOC.OCMode = TIM_OCMODE_PWM1;
  sConfigOC.Pulse = 200-1;
  sConfigOC.OCPolarity = TIM_OCPOLARITY_HIGH;
  sConfigOC.OCFastMode = TIM_OCFAST_DISABLE;
  if (HAL_TIM_PWM_ConfigChannel(&htim5, &sConfigOC, TIM_CHANNEL_4) != HAL_OK)
  {
    Error_Handler();
  }
  HAL_TIM_MspPostInit(&htim5);

}

static void MX_TIM10_Init(void)
{

  htim10.Instance = TIM10;
  htim10.Init.Prescaler = 168-1;
  htim10.Init.CounterMode = TIM_COUNTERMODE_UP;
  htim10.Init.Period = 10000-1;
  htim10.Init.ClockDivision = TIM_CLOCKDIVISION_DIV1;
  htim10.Init.AutoReloadPreload = TIM_AUTORELOAD_PRELOAD_DISABLE;
  if (HAL_TIM_Base_Init(&htim10) != HAL_OK)
  {
    Error_Handler();
  }

}

static void MX_TIM11_Init(void)
{

  htim11.Instance = TIM11;
  htim11.Init.Prescaler = 168-1;
  htim11.Init.CounterMode = TIM_COUNTERMODE_UP;
  htim11.Init.Period = 65535;
  htim11.Init.ClockDivision = TIM_CLOCKDIVISION_DIV1;
  htim11.Init.AutoReloadPreload = TIM_AUTORELOAD_PRELOAD_DISABLE;
  if (HAL_TIM_Base_Init(&htim11) != HAL_OK)
  {
    Error_Handler();
  }

}

static void MX_USART3_UART_Init(void)
{

  huart3.Instance = USART3;
  huart3.Init.BaudRate = 9600;
  huart3.Init.WordLength = UART_WORDLENGTH_8B;
  huart3.Init.StopBits = UART_STOPBITS_1;
  huart3.Init.Parity = UART_PARITY_NONE;
  huart3.Init.Mode = UART_MODE_TX_RX;
  huart3.Init.HwFlowCtl = UART_HWCONTROL_NONE;
  huart3.Init.OverSampling = UART_OVERSAMPLING_16;
  if (HAL_UART_Init(&huart3) != HAL_OK)
  {
    Error_Handler();
  }

}

static void MX_USART6_UART_Init(void)
{

  huart6.Instance = USART6;
  huart6.Init.BaudRate = 9600;
  huart6.Init.WordLength = UART_WORDLENGTH_8B;
  huart6.Init.StopBits = UART_STOPBITS_1;
  huart6.Init.Parity = UART_PARITY_NONE;
  huart6.Init.Mode = UART_MODE_TX_RX;
  huart6.Init.HwFlowCtl = UART_HWCONTROL_NONE;
  huart6.Init.OverSampling = UART_OVERSAMPLING_16;
  if (HAL_UART_Init(&huart6) != HAL_OK)
  {
    Error_Handler();
  }

}

static void MX_USB_OTG_FS_PCD_Init(void)
{

  hpcd_USB_OTG_FS.Instance = USB_OTG_FS;
  hpcd_USB_OTG_FS.Init.dev_endpoints = 4;
  hpcd_USB_OTG_FS.Init.speed = PCD_SPEED_FULL;
  hpcd_USB_OTG_FS.Init.dma_enable = DISABLE;
  hpcd_USB_OTG_FS.Init.phy_itface = PCD_PHY_EMBEDDED;
  hpcd_USB_OTG_FS.Init.Sof_enable = ENABLE;
  hpcd_USB_OTG_FS.Init.low_power_enable = DISABLE;
  hpcd_USB_OTG_FS.Init.lpm_enable = DISABLE;
  hpcd_USB_OTG_FS.Init.vbus_sensing_enable = ENABLE;
  hpcd_USB_OTG_FS.Init.use_dedicated_ep1 = DISABLE;
  if (HAL_PCD_Init(&hpcd_USB_OTG_FS) != HAL_OK)
  {
    Error_Handler();
  }

}

static void MX_GPIO_Init(void)
{
  GPIO_InitTypeDef GPIO_InitStruct = {0};

  /* GPIO Ports Clock Enable */
  __HAL_RCC_GPIOE_CLK_ENABLE();
  __HAL_RCC_GPIOC_CLK_ENABLE();
  __HAL_RCC_GPIOH_CLK_ENABLE();
  __HAL_RCC_GPIOA_CLK_ENABLE();
  __HAL_RCC_GPIOB_CLK_ENABLE();
  __HAL_RCC_GPIOF_CLK_ENABLE();
  __HAL_RCC_GPIOD_CLK_ENABLE();
  __HAL_RCC_GPIOG_CLK_ENABLE();

  /*Configure GPIO pin Output Level */
  HAL_GPIO_WritePin(GPIOE, COL1_Pin|COL2_Pin|COL3_Pin|COL4_Pin
                          |COL5_Pin|COL6_Pin|COL7_Pin|COL8_Pin, GPIO_PIN_RESET);

  /*Configure GPIO pin Output Level */
  HAL_GPIO_WritePin(DHT11_GPIO_Port, DHT11_Pin, GPIO_PIN_RESET);

  /*Configure GPIO pin Output Level */
  HAL_GPIO_WritePin(GPIOB, FND7_Pin|FND6_Pin|FND4_Pin|LD3_Pin
                          |FND5_Pin|FND2_Pin|FND1_Pin|FND9_Pin
                          |FND10_Pin|LD2_Pin, GPIO_PIN_RESET);

  /*Configure GPIO pin Output Level */
  HAL_GPIO_WritePin(ULTRASONIC_TRIGGER_GPIO_Port, ULTRASONIC_TRIGGER_Pin, GPIO_PIN_RESET);

  /*Configure GPIO pin Output Level */
  HAL_GPIO_WritePin(GPIOD, IN1_Pin|IN2_Pin|IN3_Pin|IN4_Pin
                          |ROW1_Pin|ROW2_Pin|ROW3_Pin|ROW4_Pin
                          |ROW5_Pin|ROW6_Pin|ROW7_Pin|ROW8_Pin, GPIO_PIN_RESET);

  /*Configure GPIO pin Output Level */
  HAL_GPIO_WritePin(USB_PowerSwitchOn_GPIO_Port, USB_PowerSwitchOn_Pin, GPIO_PIN_RESET);

  /*Configure GPIO pins : COL1_Pin COL2_Pin COL3_Pin COL4_Pin
                           COL5_Pin COL6_Pin COL7_Pin COL8_Pin */
  GPIO_InitStruct.Pin = COL1_Pin|COL2_Pin|COL3_Pin|COL4_Pin
                          |COL5_Pin|COL6_Pin|COL7_Pin|COL8_Pin;
  GPIO_InitStruct.Mode = GPIO_MODE_OUTPUT_PP;
  GPIO_InitStruct.Pull = GPIO_NOPULL;
  GPIO_InitStruct.Speed = GPIO_SPEED_FREQ_LOW;
  HAL_GPIO_Init(GPIOE, &GPIO_InitStruct);

  /*Configure GPIO pins : USER_Btn_Pin PHOTO0_Pin PHOTO1_Pin PHOTO2_Pin
                           PHOTO_Pin */
  GPIO_InitStruct.Pin = USER_Btn_Pin|PHOTO0_Pin|PHOTO1_Pin|PHOTO2_Pin
                          |PHOTO_Pin;
  GPIO_InitStruct.Mode = GPIO_MODE_IT_RISING;
  GPIO_InitStruct.Pull = GPIO_NOPULL;
  HAL_GPIO_Init(GPIOC, &GPIO_InitStruct);

  /*Configure GPIO pin : DHT11_Pin */
  GPIO_InitStruct.Pin = DHT11_Pin;
  GPIO_InitStruct.Mode = GPIO_MODE_OUTPUT_PP;
  GPIO_InitStruct.Pull = GPIO_NOPULL;
  GPIO_InitStruct.Speed = GPIO_SPEED_FREQ_LOW;
  HAL_GPIO_Init(DHT11_GPIO_Port, &GPIO_InitStruct);

  /*Configure GPIO pins : FND7_Pin FND6_Pin FND4_Pin LD3_Pin
                           FND5_Pin FND2_Pin FND1_Pin FND9_Pin
                           FND10_Pin LD2_Pin */
  GPIO_InitStruct.Pin = FND7_Pin|FND6_Pin|FND4_Pin|LD3_Pin
                          |FND5_Pin|FND2_Pin|FND1_Pin|FND9_Pin
                          |FND10_Pin|LD2_Pin;
  GPIO_InitStruct.Mode = GPIO_MODE_OUTPUT_PP;
  GPIO_InitStruct.Pull = GPIO_NOPULL;
  GPIO_InitStruct.Speed = GPIO_SPEED_FREQ_LOW;
  HAL_GPIO_Init(GPIOB, &GPIO_InitStruct);

  /*Configure GPIO pin : ULTRASONIC_TRIGGER_Pin */
  GPIO_InitStruct.Pin = ULTRASONIC_TRIGGER_Pin;
  GPIO_InitStruct.Mode = GPIO_MODE_OUTPUT_PP;
  GPIO_InitStruct.Pull = GPIO_NOPULL;
  GPIO_InitStruct.Speed = GPIO_SPEED_FREQ_LOW;
  HAL_GPIO_Init(ULTRASONIC_TRIGGER_GPIO_Port, &GPIO_InitStruct);

  /*Configure GPIO pins : BUTTON3_Pin BUTTON2_Pin BUTTON1_Pin BUTTON0_Pin */
  GPIO_InitStruct.Pin = BUTTON3_Pin|BUTTON2_Pin|BUTTON1_Pin|BUTTON0_Pin;
  GPIO_InitStruct.Mode = GPIO_MODE_INPUT;
  GPIO_InitStruct.Pull = GPIO_NOPULL;
  HAL_GPIO_Init(GPIOE, &GPIO_InitStruct);

  /*Configure GPIO pins : IN1_Pin IN2_Pin IN3_Pin IN4_Pin
                           ROW1_Pin ROW2_Pin ROW3_Pin ROW4_Pin
                           ROW5_Pin ROW6_Pin ROW7_Pin ROW8_Pin */
  GPIO_InitStruct.Pin = IN1_Pin|IN2_Pin|IN3_Pin|IN4_Pin
                          |ROW1_Pin|ROW2_Pin|ROW3_Pin|ROW4_Pin
                          |ROW5_Pin|ROW6_Pin|ROW7_Pin|ROW8_Pin;
  GPIO_InitStruct.Mode = GPIO_MODE_OUTPUT_PP;
  GPIO_InitStruct.Pull = GPIO_NOPULL;
  GPIO_InitStruct.Speed = GPIO_SPEED_FREQ_LOW;
  HAL_GPIO_Init(GPIOD, &GPIO_InitStruct);

  /*Configure GPIO pin : USB_PowerSwitchOn_Pin */
  GPIO_InitStruct.Pin = USB_PowerSwitchOn_Pin;
  GPIO_InitStruct.Mode = GPIO_MODE_OUTPUT_PP;
  GPIO_InitStruct.Pull = GPIO_NOPULL;
  GPIO_InitStruct.Speed = GPIO_SPEED_FREQ_LOW;
  HAL_GPIO_Init(USB_PowerSwitchOn_GPIO_Port, &GPIO_InitStruct);

  /*Configure GPIO pin : USB_OverCurrent_Pin */
  GPIO_InitStruct.Pin = USB_OverCurrent_Pin;
  GPIO_InitStruct.Mode = GPIO_MODE_INPUT;
  GPIO_InitStruct.Pull = GPIO_NOPULL;
  HAL_GPIO_Init(USB_OverCurrent_GPIO_Port, &GPIO_InitStruct);

  /* EXTI interrupt init*/
  HAL_NVIC_SetPriority(EXTI0_IRQn, 5, 0);
  HAL_NVIC_EnableIRQ(EXTI0_IRQn);

  HAL_NVIC_SetPriority(EXTI2_IRQn, 5, 0);
  HAL_NVIC_EnableIRQ(EXTI2_IRQn);

  HAL_NVIC_SetPriority(EXTI3_IRQn, 5, 0);
  HAL_NVIC_EnableIRQ(EXTI3_IRQn);

  HAL_NVIC_SetPriority(EXTI9_5_IRQn, 5, 0);
  HAL_NVIC_EnableIRQ(EXTI9_5_IRQn);

}

void StartDefaultTask(void *argument)
{
  for(;;)
  {
    osDelay(1);
  }
}

/* USER CODE BEGIN Header_Task1_func */
/**
* @brief Function implementing the Task1 thread.
* @param argument: Not used
* @retval None
*/
extern void init_dotmatrix();
/* USER CODE END Header_Task1_func */
void Task1_func(void *argument)
{
  /* USER CODE BEGIN Task1_func */
  /* Infinite loop */
  for(;;)
  {
	dotmatrix_main_test();//matrix
    osDelay(1);
  }
  /* USER CODE END Task1_func */
}

void Task2_func(void *argument)
{
  /* USER CODE BEGIN Task2_func */
  /* Infinite loop */
  for(;;)
  {
	stepmotor_main();//step
    osDelay(1);
  }
  /* USER CODE END Task2_func */
}

void Task3_func(void *argument)
{
  /* USER CODE BEGIN Task3_func */
  /* Infinite loop */
  for(;;)
  {
	  fnd();
    osDelay(1);
  }
  /* USER CODE END Task3_func */
}

void HAL_TIM_PeriodElapsedCallback(TIM_HandleTypeDef *htim)
{
  if (htim->Instance == TIM6) {
    HAL_IncTick();
  }
  /* USER CODE BEGIN Callback 1 */
	if (htim->Instance == TIM10)
	{
		TIM10_10ms_counter++;  // 10ms timer counter
		TIM10_10ms_ultrasonic++;  // ultrasonic trigger timer
	}
  /* USER CODE END Callback 1 */
}

void Error_Handler(void)
{
  __disable_irq();
  while (1)
  {
  }
}
